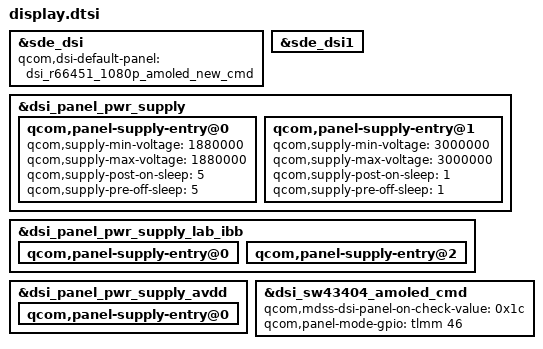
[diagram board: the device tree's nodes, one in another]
#include "dsi_r66455_1080_2340_amoled_cmd.dtsi"
#include "dsi_r66451_1080_2340_amoled_cmd.dtsi"
#include "dsi_r66451_1080_2340_amoled_new_cmd.dtsi"

/* Deletions by symlinks */
/delete-node/ &display_panel_avdd;
/delete-node/ &display_panel_avdd_default;

&sde_dsi {
	/delete-property/ avdd-supply;
	qcom,dsi-default-panel = <&dsi_r66451_1080p_amoled_new_cmd>;
};

&sde_dsi1 {
	/delete-property/ avdd-supply;
};

&dsi_panel_pwr_supply {
	qcom,panel-supply-entry@0 {
		qcom,supply-min-voltage = <1880000>;
		qcom,supply-max-voltage = <1880000>;
		qcom,supply-post-on-sleep = <5>;
		qcom,supply-pre-off-sleep = <5>;
	};

	qcom,panel-supply-entry@1 {
		qcom,supply-min-voltage = <3000000>;
		qcom,supply-max-voltage = <3000000>;
		qcom,supply-post-on-sleep = <1>;
		qcom,supply-pre-off-sleep = <1>;
	};

	/delete-node/ qcom,panel-supply-entry@2;
	/delete-node/ qcom,panel-supply-entry@3;
};

&dsi_panel_pwr_supply_lab_ibb {
	qcom,panel-supply-entry@0 {
		/delete-property/ qcom,supply-post-on-sleep;
	};

	qcom,panel-supply-entry@2 {
		/delete-property/ qcom,supply-post-on-sleep;
	};
};

&dsi_panel_pwr_supply_avdd {
	qcom,panel-supply-entry@0 {
		/delete-property/ qcom,supply-post-on-sleep;
	};
};

&dsi_sw43404_amoled_cmd {
	/delete-property/ qcom,mdss-dsi-panel-status-value;
	/delete-property/ qcom,mdss-dsi-panel-test-pin;
	qcom,mdss-dsi-panel-on-check-value = <0x1c>;
	qcom,panel-mode-gpio = <&tlmm 46 0>;
};
